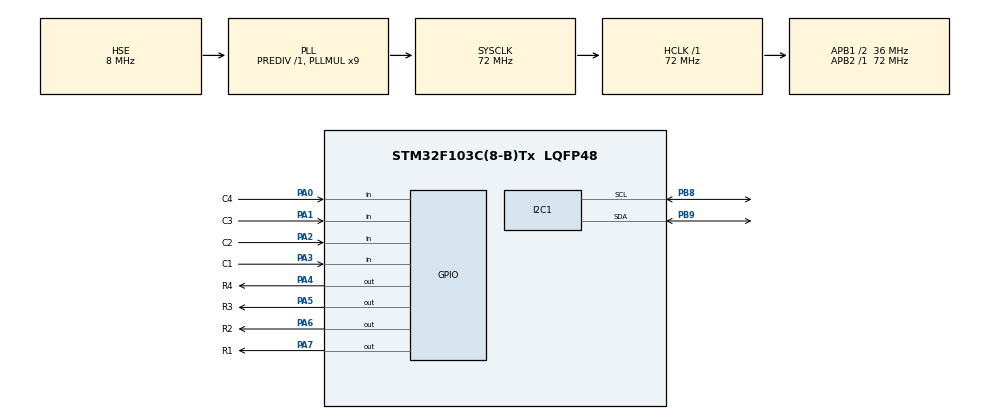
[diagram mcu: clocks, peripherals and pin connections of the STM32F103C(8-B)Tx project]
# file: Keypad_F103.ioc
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Mcu.Family=STM32F1
Mcu.Name=STM32F103C(8-B)Tx
Mcu.Package=LQFP48
NVIC.PriorityGroup=NVIC_PRIORITYGROUP_4
PA0-WKUP.GPIO_Label=C4
PA0-WKUP.GPIO_PuPd=GPIO_PULLUP
PA0-WKUP.Signal=GPIO_Input
PA1.GPIO_Label=C3
PA1.GPIO_PuPd=GPIO_PULLUP
PA1.Signal=GPIO_Input
PA13.Mode=Serial_Wire
PA13.Signal=SYS_JTMS-SWDIO
PA14.Mode=Serial_Wire
PA14.Signal=SYS_JTCK-SWCLK
PA2.GPIO_Label=C2
PA2.GPIO_PuPd=GPIO_PULLUP
PA2.Signal=GPIO_Input
PA3.GPIO_Label=C1
PA3.GPIO_PuPd=GPIO_PULLUP
PA3.Signal=GPIO_Input
PA4.GPIO_Label=R4
PA4.GPIO_ModeDefaultOutputPP=GPIO_MODE_OUTPUT_PP
PA4.GPIO_PuPd=GPIO_PULLUP
PA4.PinState=GPIO_PIN_SET
PA4.Signal=GPIO_Output
PA5.GPIO_Label=R3
PA5.GPIO_PuPd=GPIO_PULLUP
PA5.PinState=GPIO_PIN_SET
PA5.Signal=GPIO_Output
PA6.GPIO_Label=R2
PA6.GPIO_PuPd=GPIO_PULLUP
PA6.PinState=GPIO_PIN_SET
PA6.Signal=GPIO_Output
PA7.GPIO_Label=R1
PA7.GPIO_PuPd=GPIO_PULLUP
PA7.PinState=GPIO_PIN_SET
PA7.Signal=GPIO_Output
PB8.Mode=I2C
PB8.Signal=I2C1_SCL
PB9.Mode=I2C
PB9.Signal=I2C1_SDA
PD0-OSC_IN.Mode=HSE-External-Oscillator
PD0-OSC_IN.Signal=RCC_OSC_IN
PD1-OSC_OUT.Mode=HSE-External-Oscillator
PD1-OSC_OUT.Signal=RCC_OSC_OUT
ProjectManager.HeapSize=0x200
ProjectManager.StackSize=0x400
ProjectManager.TargetToolchain=STM32CubeIDE
RCC.AHBFreq_Value=72000000
RCC.APB1CLKDivider=RCC_HCLK_DIV2
RCC.APB1Freq_Value=36000000
RCC.APB1TimFreq_Value=72000000
RCC.APB2Freq_Value=72000000
RCC.APB2TimFreq_Value=72000000
RCC.HCLKFreq_Value=72000000
RCC.PLLMUL=RCC_PLL_MUL9
RCC.PLLSourceVirtual=RCC_PLLSOURCE_HSE
RCC.SYSCLKFreq_VALUE=72000000
RCC.SYSCLKSource=RCC_SYSCLKSOURCE_PLLCLK
RCC.USBFreq_Value=72000000
board=custom

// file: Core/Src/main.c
/* USER CODE BEGIN Header */
/**
  ******************************************************************************
  * @file           : main.c
  * @brief          : Main program body
  ******************************************************************************
  * @attention
  *
  * Copyright (c) 2024 STMicroelectronics.
  * All rights reserved.
  *
  * This software is licensed under terms that can be found in the LICENSE file
  * in the root directory of this software component.
  * If no LICENSE file comes with this software, it is provided AS-IS.
  *
  ******************************************************************************
  */
/* USER CODE END Header */
#include "main.h"

/* USER CODE BEGIN Includes */
#include "i2c-lcd.h"
#include <stdio.h>
/* USER CODE END Includes */

I2C_HandleTypeDef hi2c1;

void SystemClock_Config(void);
static void MX_GPIO_Init(void);
static void MX_I2C1_Init(void);

/* USER CODE BEGIN 0 */

char read_keypad (void)
{
	/* Make ROW 1 LOW and all other ROWs HIGH */
	HAL_GPIO_WritePin (R1_GPIO_Port, R1_Pin, GPIO_PIN_RESET);  //Pull the R1 low
	HAL_GPIO_WritePin (R2_GPIO_Port, R2_Pin, GPIO_PIN_SET);  // Pull the R2 High
	HAL_GPIO_WritePin (R3_GPIO_Port, R3_Pin, GPIO_PIN_SET);  // Pull the R3 High
	HAL_GPIO_WritePin (R4_GPIO_Port, R4_Pin, GPIO_PIN_SET);  // Pull the R4 High

	if (!(HAL_GPIO_ReadPin (C1_GPIO_Port, C1_Pin)))   // if the Col 1 is low
	{
		while (!(HAL_GPIO_ReadPin (C1_GPIO_Port, C1_Pin)));   // wait till the button is pressed
		return '1';
	}

	if (!(HAL_GPIO_ReadPin (C2_GPIO_Port, C2_Pin)))   // if the Col 2 is low
	{
		while (!(HAL_GPIO_ReadPin (C2_GPIO_Port, C2_Pin)));   // wait till the button is pressed
		return '2';
	}

	if (!(HAL_GPIO_ReadPin (C3_GPIO_Port, C3_Pin)))   // if the Col 3 is low
	{
		while (!(HAL_GPIO_ReadPin (C3_GPIO_Port, C3_Pin)));   // wait till the button is pressed
		return '3';
	}

	if (!(HAL_GPIO_ReadPin (C4_GPIO_Port, C4_Pin)))   // if the Col 4 is low
	{
		while (!(HAL_GPIO_ReadPin (C4_GPIO_Port, C4_Pin)));   // wait till the button is pressed
		return 'A';
	}

	/* Make ROW 2 LOW and all other ROWs HIGH */
	HAL_GPIO_WritePin (R1_GPIO_Port, R1_Pin, GPIO_PIN_SET);  //Pull the R1 low
	HAL_GPIO_WritePin (R2_GPIO_Port, R2_Pin, GPIO_PIN_RESET);  // Pull the R2 High
	HAL_GPIO_WritePin (R3_GPIO_Port, R3_Pin, GPIO_PIN_SET);  // Pull the R3 High
	HAL_GPIO_WritePin (R4_GPIO_Port, R4_Pin, GPIO_PIN_SET);  // Pull the R4 High

	if (!(HAL_GPIO_ReadPin (C1_GPIO_Port, C1_Pin)))   // if the Col 1 is low
	{
		while (!(HAL_GPIO_ReadPin (C1_GPIO_Port, C1_Pin)));   // wait till the button is pressed
		return '4';
	}

	if (!(HAL_GPIO_ReadPin (C2_GPIO_Port, C2_Pin)))   // if the Col 2 is low
	{
		while (!(HAL_GPIO_ReadPin (C2_GPIO_Port, C2_Pin)));   // wait till the button is pressed
		return '5';
	}

	if (!(HAL_GPIO_ReadPin (C3_GPIO_Port, C3_Pin)))   // if the Col 3 is low
	{
		while (!(HAL_GPIO_ReadPin (C3_GPIO_Port, C3_Pin)));   // wait till the button is pressed
		return '6';
	}

	if (!(HAL_GPIO_ReadPin (C4_GPIO_Port, C4_Pin)))   // if the Col 4 is low
	{
		while (!(HAL_GPIO_ReadPin (C4_GPIO_Port, C4_Pin)));   // wait till the button is pressed
		return 'B';
	}

	/* Make ROW 3 LOW and all other ROWs HIGH */
	HAL_GPIO_WritePin (R1_GPIO_Port, R1_Pin, GPIO_PIN_SET);  //Pull the R1 low
	HAL_GPIO_WritePin (R2_GPIO_Port, R2_Pin, GPIO_PIN_SET);  // Pull the R2 High
	HAL_GPIO_WritePin (R3_GPIO_Port, R3_Pin, GPIO_PIN_RESET);  // Pull the R3 High
	HAL_GPIO_WritePin (R4_GPIO_Port, R4_Pin, GPIO_PIN_SET);  // Pull the R4 High

	if (!(HAL_GPIO_ReadPin (C1_GPIO_Port, C1_Pin)))   // if the Col 1 is low
	{
		while (!(HAL_GPIO_ReadPin (C1_GPIO_Port, C1_Pin)));   // wait till the button is pressed
		return '7';
	}

	if (!(HAL_GPIO_ReadPin (C2_GPIO_Port, C2_Pin)))   // if the Col 2 is low
	{
		while (!(HAL_GPIO_ReadPin (C2_GPIO_Port, C2_Pin)));   // wait till the button is pressed
		return '8';
	}

	if (!(HAL_GPIO_ReadPin (C3_GPIO_Port, C3_Pin)))   // if the Col 3 is low
	{
		while (!(HAL_GPIO_ReadPin (C3_GPIO_Port, C3_Pin)));   // wait till the button is pressed
		return '9';
	}

	if (!(HAL_GPIO_ReadPin (C4_GPIO_Port, C4_Pin)))   // if the Col 4 is low
	{
		while (!(HAL_GPIO_ReadPin (C4_GPIO_Port, C4_Pin)));   // wait till the button is pressed
		return 'C';
	}

	/* Make ROW 4 LOW and all other ROWs HIGH */
	HAL_GPIO_WritePin (R1_GPIO_Port, R1_Pin, GPIO_PIN_SET);  //Pull the R1 low
	HAL_GPIO_WritePin (R2_GPIO_Port, R2_Pin, GPIO_PIN_SET);  // Pull the R2 High
	HAL_GPIO_WritePin (R3_GPIO_Port, R3_Pin, GPIO_PIN_SET);  // Pull the R3 High
	HAL_GPIO_WritePin (R4_GPIO_Port, R4_Pin, GPIO_PIN_RESET);  // Pull the R4 High

	if (!(HAL_GPIO_ReadPin (C1_GPIO_Port, C1_Pin)))   // if the Col 1 is low
	{
		while (!(HAL_GPIO_ReadPin (C1_GPIO_Port, C1_Pin)));   // wait till the button is pressed
		return '*';
	}

	if (!(HAL_GPIO_ReadPin (C2_GPIO_Port, C2_Pin)))   // if the Col 2 is low
	{
		while (!(HAL_GPIO_ReadPin (C2_GPIO_Port, C2_Pin)));   // wait till the button is pressed
		return '0';
	}

	if (!(HAL_GPIO_ReadPin (C3_GPIO_Port, C3_Pin)))   // if the Col 3 is low
	{
		while (!(HAL_GPIO_ReadPin (C3_GPIO_Port, C3_Pin)));   // wait till the button is pressed
		return '#';
	}

	if (!(HAL_GPIO_ReadPin (C4_GPIO_Port, C4_Pin)))   // if the Col 4 is low
	{
		while (!(HAL_GPIO_ReadPin (C4_GPIO_Port, C4_Pin)));   // wait till the button is pressed
		return 'D';
	}

	return 0x01;  // /if nothing is pressed

}

#define PRINTF   int __io_putchar(int ch)
PRINTF
{
	HAL_UART_Transmit(&huart2, (uint8_t*)&ch, 1, HAL_MAX_DELAY);
	return ch;
}

/* USER CODE END 0 */

int main(void)
{

  /* MCU Configuration--------------------------------------------------------*/

  /* Reset of all peripherals, Initializes the Flash interface and the Systick. */
  HAL_Init();

  /* Configure the system clock */
  SystemClock_Config();

  /* Initialize all configured peripherals */
  MX_GPIO_Init();
  MX_I2C1_Init();
  /* USER CODE BEGIN 2 */

  lcd_init();
  lcd_clear();

  lcd_put_cur(0, 0);
  lcd_send_string("KEY: ");

  /* USER CODE END 2 */

  /* Infinite loop */
  while (1)
  {

	  char key = read_keypad();
	  if (key!=0x01)
	  {
		  lcd_send_data(key);
	  }

  }
}

void SystemClock_Config(void)
{
  RCC_OscInitTypeDef RCC_OscInitStruct = {0};
  RCC_ClkInitTypeDef RCC_ClkInitStruct = {0};

  /** Initializes the RCC Oscillators according to the specified parameters
  * in the RCC_OscInitTypeDef structure.
  */
  RCC_OscInitStruct.OscillatorType = RCC_OSCILLATORTYPE_HSE;
  RCC_OscInitStruct.HSEState = RCC_HSE_ON;
  RCC_OscInitStruct.HSEPredivValue = RCC_HSE_PREDIV_DIV1;
  RCC_OscInitStruct.HSIState = RCC_HSI_ON;
  RCC_OscInitStruct.PLL.PLLState = RCC_PLL_ON;
  RCC_OscInitStruct.PLL.PLLSource = RCC_PLLSOURCE_HSE;
  RCC_OscInitStruct.PLL.PLLMUL = RCC_PLL_MUL9;
  if (HAL_RCC_OscConfig(&RCC_OscInitStruct) != HAL_OK)
  {
    Error_Handler();
  }

  /** Initializes the CPU, AHB and APB buses clocks
  */
  RCC_ClkInitStruct.ClockType = RCC_CLOCKTYPE_HCLK|RCC_CLOCKTYPE_SYSCLK
                              |RCC_CLOCKTYPE_PCLK1|RCC_CLOCKTYPE_PCLK2;
  RCC_ClkInitStruct.SYSCLKSource = RCC_SYSCLKSOURCE_PLLCLK;
  RCC_ClkInitStruct.AHBCLKDivider = RCC_SYSCLK_DIV1;
  RCC_ClkInitStruct.APB1CLKDivider = RCC_HCLK_DIV2;
  RCC_ClkInitStruct.APB2CLKDivider = RCC_HCLK_DIV1;

  if (HAL_RCC_ClockConfig(&RCC_ClkInitStruct, FLASH_LATENCY_2) != HAL_OK)
  {
    Error_Handler();
  }
}

static void MX_I2C1_Init(void)
{

  hi2c1.Instance = I2C1;
  hi2c1.Init.ClockSpeed = 100000;
  hi2c1.Init.DutyCycle = I2C_DUTYCYCLE_2;
  hi2c1.Init.OwnAddress1 = 0;
  hi2c1.Init.AddressingMode = I2C_ADDRESSINGMODE_7BIT;
  hi2c1.Init.DualAddressMode = I2C_DUALADDRESS_DISABLE;
  hi2c1.Init.OwnAddress2 = 0;
  hi2c1.Init.GeneralCallMode = I2C_GENERALCALL_DISABLE;
  hi2c1.Init.NoStretchMode = I2C_NOSTRETCH_DISABLE;
  if (HAL_I2C_Init(&hi2c1) != HAL_OK)
  {
    Error_Handler();
  }

}

static void MX_GPIO_Init(void)
{
  GPIO_InitTypeDef GPIO_InitStruct = {0};

  /* GPIO Ports Clock Enable */
  __HAL_RCC_GPIOD_CLK_ENABLE();
  __HAL_RCC_GPIOA_CLK_ENABLE();
  __HAL_RCC_GPIOB_CLK_ENABLE();

  /*Configure GPIO pin Output Level */
  HAL_GPIO_WritePin(GPIOA, R4_Pin|R3_Pin|R2_Pin|R1_Pin, GPIO_PIN_SET);

  /*Configure GPIO pins : C4_Pin C3_Pin C2_Pin C1_Pin */
  GPIO_InitStruct.Pin = C4_Pin|C3_Pin|C2_Pin|C1_Pin;
  GPIO_InitStruct.Mode = GPIO_MODE_INPUT;
  GPIO_InitStruct.Pull = GPIO_PULLUP;
  HAL_GPIO_Init(GPIOA, &GPIO_InitStruct);

  /*Configure GPIO pins : R4_Pin R3_Pin R2_Pin R1_Pin */
  GPIO_InitStruct.Pin = R4_Pin|R3_Pin|R2_Pin|R1_Pin;
  GPIO_InitStruct.Mode = GPIO_MODE_OUTPUT_PP;
  GPIO_InitStruct.Pull = GPIO_PULLUP;
  GPIO_InitStruct.Speed = GPIO_SPEED_FREQ_LOW;
  HAL_GPIO_Init(GPIOA, &GPIO_InitStruct);

}

void Error_Handler(void)
{
  __disable_irq();
  while (1)
  {
  }
}
